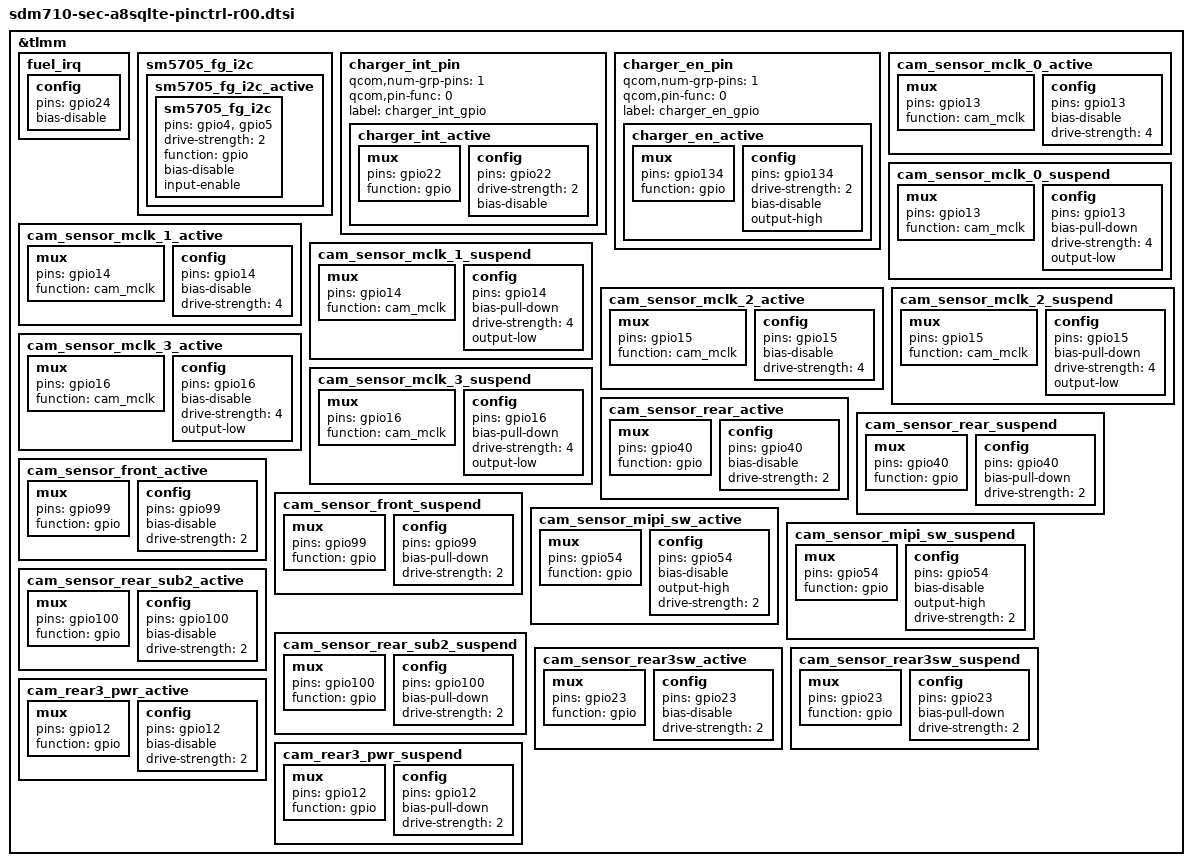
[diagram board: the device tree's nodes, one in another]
/* Copyright (c) 2016-2017, The Linux Foundation. All rights reserved.
 *
 * This program is free software; you can redistribute it and/or modify
 * it under the terms of the GNU General Public License version 2 and
 * only version 2 as published by the Free Software Foundation.
 *
 * This program is distributed in the hope that it will be useful,
 * but WITHOUT ANY WARRANTY; without even the implied warranty of
 * MERCHANTABILITY or FITNESS FOR A PARTICULAR PURPOSE.  See the
 * GNU General Public License for more details.
 */

#include "sdm710-sec-a8sqlte-pinctrl-common.dtsi"
#include "sdm710-sec-a8sqlte-audio-pinctrl.dtsi"

&tlmm {
	fuel_irq: fuel_irq {
		config {
			pins = "gpio24";
			bias-disable;         /* No PULL */
		};
	};

	sm5705_fg_i2c {
		sm5705_fg_i2c_active: sm5705_fg_i2c_active {
			sm5705_fg_i2c {
				pins = "gpio4", "gpio5";
				drive-strength = <2>;
				function = "gpio";
				bias-disable;
				input-enable;
			};
		};
	};
	
	charger_int_pin {
		//qcom,pins = <&gp 69>;
		qcom,num-grp-pins = <1>;
		qcom,pin-func = <0>;
		label = "charger_int_gpio";
		charger_int_active: charger_int_active {
			mux {
				pins = "gpio22";
				function = "gpio";				
			};
			config {
				pins = "gpio22";
				drive-strength = <2>;
				bias-disable;         /* No PULL */
			};
		};
	};
 
 	charger_en_pin {
 		//qcom,pins = <&gp 63>;
		qcom,num-grp-pins = <1>;
		qcom,pin-func = <0>;
		label = "charger_en_gpio";
		charger_en_active: charger_en_active {
			mux {
				pins = "gpio134";
				function = "gpio";				
 			};
			config {
				pins = "gpio134";
				drive-strength = <2>;
				bias-disable;         /* No PULL */
				output-high;
			};
		};
	};

	cam_sensor_mclk_0_active: cam_sensor_mclk_0_active {
	/* REAR MCLK */
		mux {
			pins = "gpio13";
			function = "cam_mclk";
		};
		config {
			pins = "gpio13";
			bias-disable; /* No PULL */
			drive-strength = <4>; /* 2 MA */
		};
	};

	cam_sensor_mclk_0_suspend: cam_sensor_mclk_0_suspend {
	/* REAR MCLK */
		mux {
			pins = "gpio13";
			function = "cam_mclk";
		};
		config {
			pins = "gpio13";
			bias-pull-down; /* PULL DOWN */
			drive-strength = <4>; /* 2 MA */
			output-low;
		};
	};

	cam_sensor_mclk_1_active: cam_sensor_mclk_1_active {
	/* FRONT MCLK */
		mux {
			pins = "gpio14";
			function = "cam_mclk";
		};
		config {
			pins = "gpio14";
			bias-disable; /* No PULL */
			drive-strength = <4>; /* 2 MA */
		};
	};

	cam_sensor_mclk_1_suspend: cam_sensor_mclk_1_suspend {
	/* FRONT MCLK */
		mux {
			pins = "gpio14";
			function = "cam_mclk";
		};
		config {
			pins = "gpio14";
			bias-pull-down; /* PULL DOWN */
			drive-strength = <4>; /* 2 MA */
			output-low;
		};
	};

	cam_sensor_mclk_2_active: cam_sensor_mclk_2_active {
	/* REAR 5M */
		mux {
			pins = "gpio15";
			function = "cam_mclk";
		};
		config {
			pins = "gpio15";
			bias-disable; /* No PULL */
			drive-strength = <4>; /* 2 MA */
		};
	};

	cam_sensor_mclk_2_suspend: cam_sensor_mclk_2_suspend {
	/* REAR 5M */
		mux {
			pins = "gpio15";
			function = "cam_mclk";
		};
		config {
			pins = "gpio15";
			bias-pull-down; /* PULL DOWN */
			drive-strength = <4>; /* 2 MA */
			output-low;
		};
	};

	cam_sensor_mclk_3_active: cam_sensor_mclk_3_active {
	/* REAR SW-8M */
		mux {
			pins = "gpio16";
			function = "cam_mclk";
		};
		config {
			pins = "gpio16";
			bias-disable; /* No PULL */
			drive-strength = <4>; /* 2 MA */
			output-low;
		};
	};

	cam_sensor_mclk_3_suspend: cam_sensor_mclk_3_suspend {
	/* REAR SW-8M */
		mux {
			pins = "gpio16";
			function = "cam_mclk";
		};
		config {
			pins = "gpio16";
			bias-pull-down; /* PULL DOWN */
			drive-strength = <4>; /* 2 MA */
			output-low;
		};
	};	

	cam_sensor_rear_active: cam_sensor_rear_active {
	/* REAR RESET */
		mux {
			pins = "gpio40";
			function = "gpio";
		};
		config {
			pins = "gpio40";
			bias-disable; /* No PULL */
			drive-strength = <2>; /* 2 MA */
		};
	};

	cam_sensor_rear_suspend: cam_sensor_rear_suspend {
	/* REAR RESET */
		mux {
			pins = "gpio40";
			function = "gpio";
		};
		config {
			pins = "gpio40";
			bias-pull-down; /* PULL DOWN */
			drive-strength = <2>; /* 2 MA */
		};
	};
		
	cam_sensor_front_active: cam_sensor_front_active {
		/* FRONT RESET */
		mux {
			pins = "gpio99";
			function = "gpio";
		};
		config {
			pins = "gpio99";
			bias-disable; /* No PULL */
			drive-strength = <2>; /* 2 MA */
		};
	};

	cam_sensor_front_suspend: cam_sensor_front_suspend {
		/* FRONT RESET */
		mux {
			pins = "gpio99";
			function = "gpio";
		};
		config {
			pins = "gpio99";
			bias-pull-down; /* PULL DOWN */
			drive-strength = <2>; /* 2 MA */
		};
	};
	cam_sensor_mipi_sw_active: cam_sensor_mipi_sw_active {
	/* MIPI_SWITCH */
		mux {
			pins = "gpio54";
			function = "gpio";
		};
		config {
			pins = "gpio54";
			bias-disable; /* No PULL */
			output-high;
			drive-strength = <2>; /* 2 MA */
		};
	};

	cam_sensor_mipi_sw_suspend: cam_sensor_mipi_sw_suspend {
	/* MIPI_SWITCH */
		mux {
			pins = "gpio54";
			function = "gpio";
		};
		config {
			pins = "gpio54";
			bias-disable; /* No PULL */
			output-high;
			drive-strength = <2>; /* 2 MA */
		};
	};
	cam_sensor_rear_sub2_active: cam_sensor_rear_sub2_active {
	/* REAR SUB2 RESET*/
		mux {
			pins = "gpio100";
			function = "gpio";
		};
		config {
			pins = "gpio100";
			bias-disable; /* No PULL */
			drive-strength = <2>; /* 2 MA */
		};
	};

	cam_sensor_rear_sub2_suspend: cam_sensor_rear_sub2_suspend {
	/* REAR SUB2 RESET */
		mux {
			pins = "gpio100";
			function = "gpio";
		};
		config {
			pins = "gpio100";
			bias-pull-down; /* PULL DOWN */
			drive-strength = <2>; /* 2 MA */
		};
	};
	cam_sensor_rear3sw_active: cam_sensor_rear3sw_active {
	/* REAR SUB2 RESET*/
		mux {
			pins = "gpio23";
			function = "gpio";
		};
		config {
			pins = "gpio23";
			bias-disable; /* No PULL */
			drive-strength = <2>; /* 2 MA */
		};
	};

	cam_sensor_rear3sw_suspend: cam_sensor_rear3sw_suspend {
	/* REAR SUB2 RESET */
		mux {
			pins = "gpio23";
			function = "gpio";
		};
		config {
			pins = "gpio23";
			bias-pull-down; /* PULL DOWN */
			drive-strength = <2>; /* 2 MA */
		};
	};
	cam_rear3_pwr_active: cam_rear3_pwr_active {
	/* REAR SUB2 RESET*/
		mux {
			pins = "gpio12";
			function = "gpio";
		};
		config {
			pins = "gpio12";
			bias-disable; /* No PULL */
			drive-strength = <2>; /* 2 MA */
		};
	};

	cam_rear3_pwr_suspend: cam_rear3_pwr_suspend {
	/* REAR SUB2 RESET */
		mux {
			pins = "gpio12";
			function = "gpio";
		};
		config {
			pins = "gpio12";
			bias-pull-down; /* PULL DOWN */
			drive-strength = <2>; /* 2 MA */
		};
	};		
		
};
